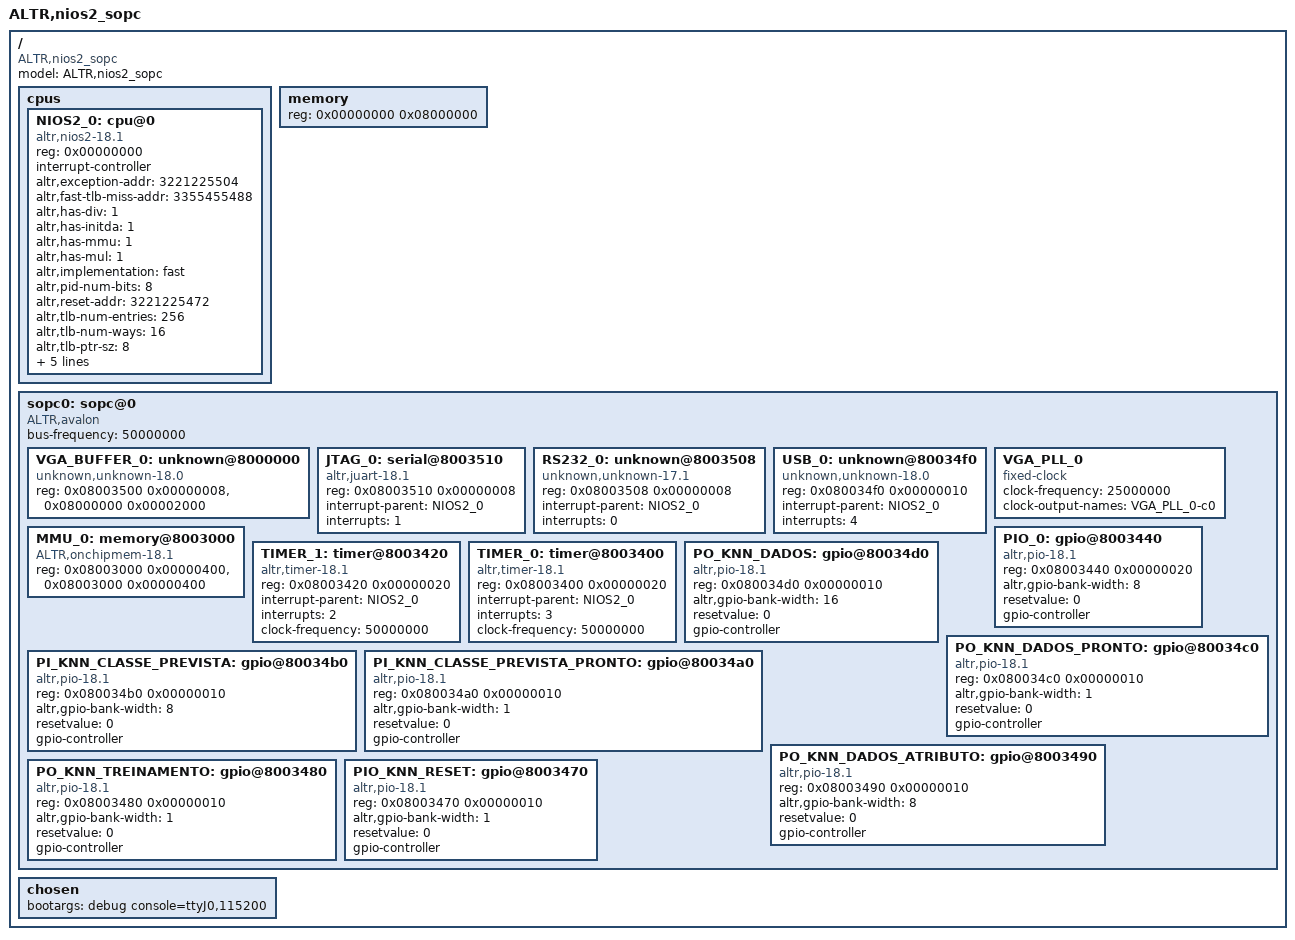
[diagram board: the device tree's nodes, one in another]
/*
 * This devicetree is generated by sopc2dts version unknown on Mon Aug 26 21:15:27 BRT 2019
 * Sopc2dts is written by Walter Goossens <waltergoossens@home.nl>
 * in cooperation with the nios2 community <nios2-dev@lists.rocketboards.org>
 */
/dts-v1/;

/ {
	model = "ALTR,nios2_sopc";
	compatible = "ALTR,nios2_sopc";
	#address-cells = <1>;
	#size-cells = <1>;

	cpus {
		#address-cells = <1>;
		#size-cells = <0>;

		NIOS2_0: cpu@0 {
			device_type = "cpu";
			compatible = "altr,nios2-18.1", "altr,nios2-1.1";
			reg = <0x00000000>;
			interrupt-controller;
			#interrupt-cells = <1>;
			altr,exception-addr = <3221225504>;	/* embeddedsw.dts.params.altr,exception-addr type NUMBER */
			altr,fast-tlb-miss-addr = <3355455488>;	/* embeddedsw.dts.params.altr,fast-tlb-miss-addr type NUMBER */
			altr,has-div = <1>;	/* embeddedsw.dts.params.altr,has-div type NUMBER */
			altr,has-initda = <1>;	/* embeddedsw.dts.params.altr,has-initda type NUMBER */
			altr,has-mmu = <1>;	/* embeddedsw.dts.params.altr,has-mmu type NUMBER */
			altr,has-mul = <1>;	/* embeddedsw.dts.params.altr,has-mul type NUMBER */
			altr,implementation = "fast";	/* embeddedsw.dts.params.altr,implementation type STRING */
			altr,pid-num-bits = <8>;	/* embeddedsw.dts.params.altr,pid-num-bits type NUMBER */
			altr,reset-addr = <3221225472>;	/* embeddedsw.dts.params.altr,reset-addr type NUMBER */
			altr,tlb-num-entries = <256>;	/* embeddedsw.dts.params.altr,tlb-num-entries type NUMBER */
			altr,tlb-num-ways = <16>;	/* embeddedsw.dts.params.altr,tlb-num-ways type NUMBER */
			altr,tlb-ptr-sz = <8>;	/* embeddedsw.dts.params.altr,tlb-ptr-sz type NUMBER */
			clock-frequency = <50000000>;	/* embeddedsw.dts.params.clock-frequency type NUMBER */
			dcache-line-size = <32>;	/* embeddedsw.dts.params.dcache-line-size type NUMBER */
			dcache-size = <2048>;	/* embeddedsw.dts.params.dcache-size type NUMBER */
			icache-line-size = <32>;	/* embeddedsw.dts.params.icache-line-size type NUMBER */
			icache-size = <4096>;	/* embeddedsw.dts.params.icache-size type NUMBER */
		}; //end cpu@0 (NIOS2_0)
	}; //end cpus

	memory {
		device_type = "memory";
		reg = <0x00000000 0x08000000>;
	}; //end memory

	sopc0: sopc@0 {
		device_type = "soc";
		ranges;
		#address-cells = <1>;
		#size-cells = <1>;
		compatible = "ALTR,avalon", "simple-bus";
		bus-frequency = <50000000>;

		VGA_BUFFER_0: unknown@8000000 {
			compatible = "unknown,unknown-18.0";
			reg = <0x08003500 0x00000008>,
				<0x08000000 0x00002000>;
			reg-names = "avalon_char_control_slave", "avalon_char_buffer_slave";
		}; //end unknown@8000000 (VGA_BUFFER_0)

		JTAG_0: serial@8003510 {
			compatible = "altr,juart-18.1", "altr,juart-1.0";
			reg = <0x08003510 0x00000008>;
			interrupt-parent = <&NIOS2_0>;
			interrupts = <1>;
		}; //end serial@8003510 (JTAG_0)

		RS232_0: unknown@8003508 {
			compatible = "unknown,unknown-17.1";
			reg = <0x08003508 0x00000008>;
			interrupt-parent = <&NIOS2_0>;
			interrupts = <0>;
		}; //end unknown@8003508 (RS232_0)

		USB_0: unknown@80034f0 {
			compatible = "unknown,unknown-18.0";
			reg = <0x080034f0 0x00000010>;
			interrupt-parent = <&NIOS2_0>;
			interrupts = <4>;
		}; //end unknown@80034f0 (USB_0)

		VGA_PLL_0: VGA_PLL_0 {
			compatible = "fixed-clock";
			#clock-cells = <0>;
			clock-frequency = <25000000>;	/* 25,00 MHz */
			clock-output-names = "VGA_PLL_0-c0";
		}; //end VGA_PLL_0 (VGA_PLL_0)

		MMU_0: memory@8003000 {
			device_type = "memory";
			compatible = "ALTR,onchipmem-18.1";
			reg = <0x08003000 0x00000400>,
				<0x08003000 0x00000400>;
			reg-names = "s1", "s2";
		}; //end memory@8003000 (MMU_0)

		PIO_0: gpio@8003440 {
			compatible = "altr,pio-18.1", "altr,pio-1.0";
			reg = <0x08003440 0x00000020>;
			altr,gpio-bank-width = <8>;	/* embeddedsw.dts.params.altr,gpio-bank-width type NUMBER */
			resetvalue = <0>;	/* embeddedsw.dts.params.resetvalue type NUMBER */
			#gpio-cells = <2>;
			gpio-controller;
		}; //end gpio@8003440 (PIO_0)

		TIMER_1: timer@8003420 {
			compatible = "altr,timer-18.1", "altr,timer-1.0";
			reg = <0x08003420 0x00000020>;
			interrupt-parent = <&NIOS2_0>;
			interrupts = <2>;
			clock-frequency = <50000000>;	/* embeddedsw.dts.params.clock-frequency type NUMBER */
		}; //end timer@8003420 (TIMER_1)

		TIMER_0: timer@8003400 {
			compatible = "altr,timer-18.1", "altr,timer-1.0";
			reg = <0x08003400 0x00000020>;
			interrupt-parent = <&NIOS2_0>;
			interrupts = <3>;
			clock-frequency = <50000000>;	/* embeddedsw.dts.params.clock-frequency type NUMBER */
		}; //end timer@8003400 (TIMER_0)

		PO_KNN_DADOS: gpio@80034d0 {
			compatible = "altr,pio-18.1", "altr,pio-1.0";
			reg = <0x080034d0 0x00000010>;
			altr,gpio-bank-width = <16>;	/* embeddedsw.dts.params.altr,gpio-bank-width type NUMBER */
			resetvalue = <0>;	/* embeddedsw.dts.params.resetvalue type NUMBER */
			#gpio-cells = <2>;
			gpio-controller;
		}; //end gpio@80034d0 (PO_KNN_DADOS)

		PO_KNN_DADOS_PRONTO: gpio@80034c0 {
			compatible = "altr,pio-18.1", "altr,pio-1.0";
			reg = <0x080034c0 0x00000010>;
			altr,gpio-bank-width = <1>;	/* embeddedsw.dts.params.altr,gpio-bank-width type NUMBER */
			resetvalue = <0>;	/* embeddedsw.dts.params.resetvalue type NUMBER */
			#gpio-cells = <2>;
			gpio-controller;
		}; //end gpio@80034c0 (PO_KNN_DADOS_PRONTO)

		PI_KNN_CLASSE_PREVISTA: gpio@80034b0 {
			compatible = "altr,pio-18.1", "altr,pio-1.0";
			reg = <0x080034b0 0x00000010>;
			altr,gpio-bank-width = <8>;	/* embeddedsw.dts.params.altr,gpio-bank-width type NUMBER */
			resetvalue = <0>;	/* embeddedsw.dts.params.resetvalue type NUMBER */
			#gpio-cells = <2>;
			gpio-controller;
		}; //end gpio@80034b0 (PI_KNN_CLASSE_PREVISTA)

		PI_KNN_CLASSE_PREVISTA_PRONTO: gpio@80034a0 {
			compatible = "altr,pio-18.1", "altr,pio-1.0";
			reg = <0x080034a0 0x00000010>;
			altr,gpio-bank-width = <1>;	/* embeddedsw.dts.params.altr,gpio-bank-width type NUMBER */
			resetvalue = <0>;	/* embeddedsw.dts.params.resetvalue type NUMBER */
			#gpio-cells = <2>;
			gpio-controller;
		}; //end gpio@80034a0 (PI_KNN_CLASSE_PREVISTA_PRONTO)

		PO_KNN_DADOS_ATRIBUTO: gpio@8003490 {
			compatible = "altr,pio-18.1", "altr,pio-1.0";
			reg = <0x08003490 0x00000010>;
			altr,gpio-bank-width = <8>;	/* embeddedsw.dts.params.altr,gpio-bank-width type NUMBER */
			resetvalue = <0>;	/* embeddedsw.dts.params.resetvalue type NUMBER */
			#gpio-cells = <2>;
			gpio-controller;
		}; //end gpio@8003490 (PO_KNN_DADOS_ATRIBUTO)

		PO_KNN_TREINAMENTO: gpio@8003480 {
			compatible = "altr,pio-18.1", "altr,pio-1.0";
			reg = <0x08003480 0x00000010>;
			altr,gpio-bank-width = <1>;	/* embeddedsw.dts.params.altr,gpio-bank-width type NUMBER */
			resetvalue = <0>;	/* embeddedsw.dts.params.resetvalue type NUMBER */
			#gpio-cells = <2>;
			gpio-controller;
		}; //end gpio@8003480 (PO_KNN_TREINAMENTO)

		PIO_KNN_RESET: gpio@8003470 {
			compatible = "altr,pio-18.1", "altr,pio-1.0";
			reg = <0x08003470 0x00000010>;
			altr,gpio-bank-width = <1>;	/* embeddedsw.dts.params.altr,gpio-bank-width type NUMBER */
			resetvalue = <0>;	/* embeddedsw.dts.params.resetvalue type NUMBER */
			#gpio-cells = <2>;
			gpio-controller;
		}; //end gpio@8003470 (PIO_KNN_RESET)
	}; //end sopc@0 (sopc0)

	chosen {
		bootargs = "debug console=ttyJ0,115200";
	}; //end chosen
}; //end /
